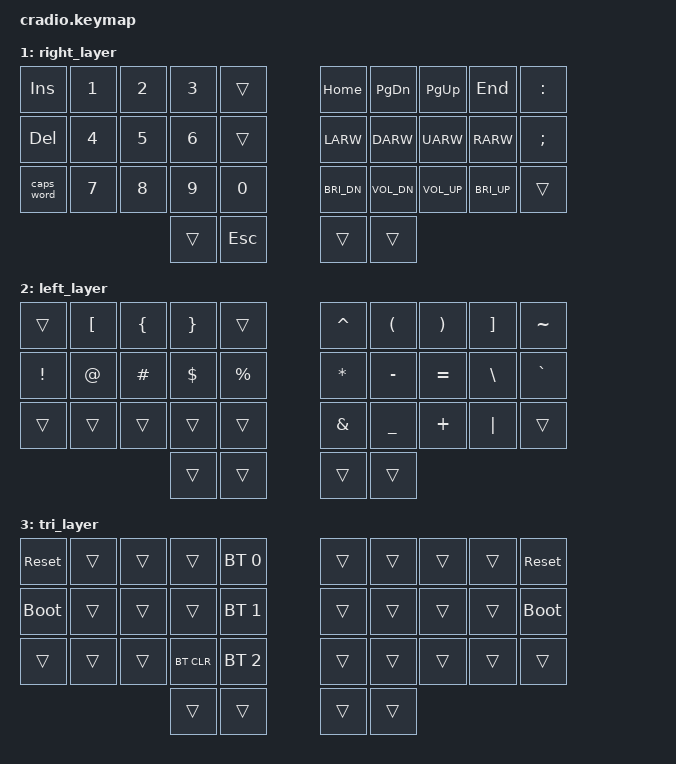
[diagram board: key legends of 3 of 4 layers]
// Copyright (c) 2022 The ZMK Contributors
// SPDX-License-Identifier: MIT

#include <behaviors.dtsi>
#include <dt-bindings/zmk/keys.h>
#include <dt-bindings/zmk/bt.h>

// Home row mods macro
#define HRML(k1,k2,k3,k4) &ht LGUI k1 &ht LALT k2  &ht LCTRL k3  &ht LSHFT k4
#define HRMR(k1,k2,k3,k4) &ht RSHFT k1 &ht RCTRL k2  &ht RALT k3  &ht RGUI k4

/ {
    behaviors {
        ht: hold_tap {
            label = "hold_tap";
            compatible = "zmk,behavior-hold-tap";
            #binding-cells = <2>;
            flavor = "tap-preferred";
            tapping-term-ms = <220>;
            quick-tap-ms = <150>;
            global-quick-tap;
            bindings = <&kp>, <&kp>;
        };
    };

    conditional_layers {
        compatible = "zmk,conditional-layers";
        tri_layer {
            if-layers = <1 2>;
            then-layer = <3>;
        };
    };

    combos {
        compatible = "zmk,combos";
        
        combo_alfred {
            timeout-ms = <50>;
            key-positions = <11 12 13>;
            bindings = <&kp LA(SPACE)>;
        };
        
        combo_esc {
            timeout-ms = <50>;
            key-positions = <1 2>;
            bindings = <&kp ESC>;
        };

        combo_esc2 {
            timeout-ms = <50>;
            key-positions = <7 8>;
            bindings = <&kp ESC>;
        };
        
        combo_undo {
            timeout-ms = <50>;
            key-positions = <20 21>;
            bindings = <&kp LG(Z)>;
        };
        
        combo_cut {
            timeout-ms = <50>;
            key-positions = <21 23>;
            bindings = <&kp LG(X)>;
        };
        
         combo_copy {
            timeout-ms = <50>;
            key-positions = <21 22>;
            bindings = <&kp LG(C)>;
        };
        
         combo_paste {
            timeout-ms = <50>;
            key-positions = <22 23>;
            bindings = <&kp LG(V)>;
        };
        
         combo_screen_left {
            timeout-ms = <50>;
            key-positions = <26 27>;
            bindings = <&kp LC(LEFT)>;
        };
        
         combo_screen_right {
            timeout-ms = <50>;
            key-positions = <27 28>;
            bindings = <&kp LC(RIGHT)>;
        };
        
         combo_volup {
            timeout-ms = <50>;
            key-positions = <7 17>;
            bindings = <&kp C_VOL_UP>;
        };
        
         combo_voldown {
            timeout-ms = <50>;
            key-positions = <17 27>;
            bindings = <&kp C_VOL_DN>;
        };
        
         combo_playpause {
            timeout-ms = <50>;
            key-positions = <26 28>;
            bindings = <&kp C_PLAY_PAUSE>;
        };
    };
        
    keymap {
        compatible = "zmk,keymap";
        default_layer {
            bindings = <
        //╭──────────┬──────────┬──────────┬──────────┬──────────╮   ╭──────────┬──────────┬──────────┬──────────┬──────────╮
        //│  Q       │  W       │  E       │  R       │  T       │   │  Y       │  U       │  I       │  O       │  P       │
            &kp Q      &kp W      &kp E      &kp R      &kp T          &kp Y      &kp U      &kp I      &kp O      &kp P
        //├──────────┼──────────┼──────────┼──────────┼──────────┤   ├──────────┼──────────┼──────────┼──────────┼──────────┤
        //│  A       │  S       │  D       │  F       │  G       │   │  H       │  J       │  K       │  L       │ ' "      │
            HRML(A,        S,         D,         F)     &kp G          &kp H      HRMR(J,        K,         L,        SQT)
        //├──────────┼──────────┼──────────┼──────────┼──────────┤   ├──────────┼──────────┼──────────┼──────────┼──────────┤
        //│  Z       │  X       │  C       │  V       │  B       │   │  N       │  M       │ , <      │ . >      │ / ?      │
            &kp Z      &kp X      &kp C      &kp V      &kp B          &kp N      &kp M      &kp COMMA  &kp DOT    &kp FSLH
        //╰──────────┴──────────┴──────────┼──────────┼──────────┤   ├──────────┼──────────┼──────────┴──────────┴──────────╯
                                            &lt 2 TAB   &kp SPACE     &kp ENTER  &lt 1 BSPC
        //                                 ╰──────────┴──────────╯   ╰──────────┴──────────╯
            >;
        };

        right_layer {
            bindings = <
        //╭──────────┬──────────┬──────────┬──────────┬──────────╮   ╭──────────┬──────────┬──────────┬──────────┬──────────╮
        //│ INSERT   │  1       │  2       │  3       │          │   │ HOME     │ PAGE DN  │ PAGE UP  │ END      │  :       │
            &kp INS    &kp N1     &kp N2     &kp N3     &trans         &kp HOME   &kp PG_DN  &kp PG_UP  &kp END    &kp COLON
        //├──────────┼──────────┼──────────┼──────────┼──────────┤   ├──────────┼──────────┼──────────┼──────────┼──────────┤
        //│ DELETE   │  4       │  5       │  6       │          │   │ LEFT     │ DOWN     │ UP       │ RIGHT    │  ;       │
            &kp DEL    &kp N4     &kp N5     &kp N6     &trans         &kp LARW   &kp DARW   &kp UARW   &kp RARW   &kp SEMI
        //├──────────┼──────────┼──────────┼──────────┼──────────┤   ├──────────┼──────────┼──────────┼──────────┼──────────┤
        //│ CAPS     │  7       │  8       │  9       │  0       │   │ BRI DN   │ VOLUME DN│ VOLUME UP│ BRI UP   │          │
           &caps_word  &kp N7     &kp N8     &kp N9     &kp N0       &kp C_BRI_DN &kp C_VOL_DN &kp C_VOL_UP &kp C_BRI_UP &trans
        //╰──────────┴──────────┴──────────┼──────────┼──────────┤   ├──────────┼──────────┼──────────┴──────────┴──────────╯
                                             &trans     &kp ESC        &trans     &trans
        //                                 ╰──────────┴──────────╯   ╰──────────┴──────────╯
            >;
        };

        left_layer {
            bindings = <
        //╭──────────┬──────────┬──────────┬──────────┬──────────╮   ╭──────────┬──────────┬──────────┬──────────┬──────────╮
        //│          │  [       │  {       │  }       │          │   │  ^       │  (       │  )       │  ]       │  ~       │
            &trans     &kp LBKT   &kp LBRC   &kp RBRC   &trans         &kp CARET  &kp LPAR   &kp RPAR   &kp RBKT   &kp TILDE
        //├──────────┼──────────┼──────────┼──────────┼──────────┤   ├──────────┼──────────┼──────────┼──────────┼──────────┤
        //│  !       │  @       │  #       │  $       │  %       │   │  *       │  -       │  =       │  \       │  `       │
            &kp EXCL   &kp AT     &kp HASH   &kp DLLR   &kp PRCNT      &kp ASTRK  &kp MINUS  &kp EQUAL  &kp BSLH   &kp GRAVE
        //├──────────┼──────────┼──────────┼──────────┼──────────┤   ├──────────┼──────────┼──────────┼──────────┼──────────┤
        //│          │          │          │          │          │   │  &       │  _       │  +       │  │       │          │
            &trans     &trans     &trans     &trans     &trans         &kp AMPS   &kp UNDER  &kp PLUS   &kp PIPE   &trans
        //╰──────────┴──────────┴──────────┼──────────┼──────────┤   ├──────────┼──────────┼──────────┴──────────┴──────────╯
                                             &trans     &trans         &trans     &trans
        //                                 ╰──────────┴──────────╯   ╰──────────┴──────────╯
            >;
        };

        tri_layer {
            bindings = <
        //╭──────────┬──────────┬──────────┬──────────┬──────────╮   ╭──────────┬──────────┬──────────┬──────────┬──────────╮
        //│ RESET    │          │          │          │PROFILE 0 │   │          │          │          │          │  RESET   │
           &sys_reset     &trans     &trans     &trans    &bt BT_SEL 0    &trans     &trans     &trans     &trans &sys_reset
        //├──────────┼──────────┼──────────┼──────────┼──────────┤   ├──────────┼──────────┼──────────┼──────────┼──────────┤
        //│BOOTLOADER│          │          │          │PROFILE 1 │   │          │          │          │          │BOOTLOADER│
          &bootloader  &trans     &trans     &trans    &bt BT_SEL 1    &trans     &trans     &trans     &trans    &bootloader
        //├──────────┼──────────┼──────────┼──────────┼──────────┤   ├──────────┼──────────┼──────────┼──────────┼──────────┤
        //│          │          │          │ CLEAR BT │PROFILE 2 │   │          │          │          │          │          │
            &trans     &trans     &trans    &bt BT_CLR &bt BT_SEL 2    &trans     &trans     &trans     &trans     &trans
        //╰──────────┴──────────┴──────────┼──────────┼──────────┤   ├──────────┼──────────┼──────────┴──────────┴──────────╯
                                             &trans     &trans         &trans     &trans
        //                                 ╰──────────┴──────────╯   ╰──────────┴──────────╯
            >;
        };
    };
};
